# ESP32-P4 register map
Vendor: ESPRESSIF SYSTEMS (SHANGHAI) CO., LTD.; Series: ESP32 P-Series; File version: 2
CPU: RV32IMAFC r0p0, little endian, no MPU, FPU, 0 interrupt priority bits
Address unit: 32 bits
Registers are 32-bit, read-write, reset 0x0 unless marked. A register's access mark holds for its fields unless they carry their own. Offsets are from the block's base; [hi:lo] are bit positions; {n}, {i} and the like mark numbered series.

## LP_WDT — Low-power Watchdog Timer
Base 0x50116000
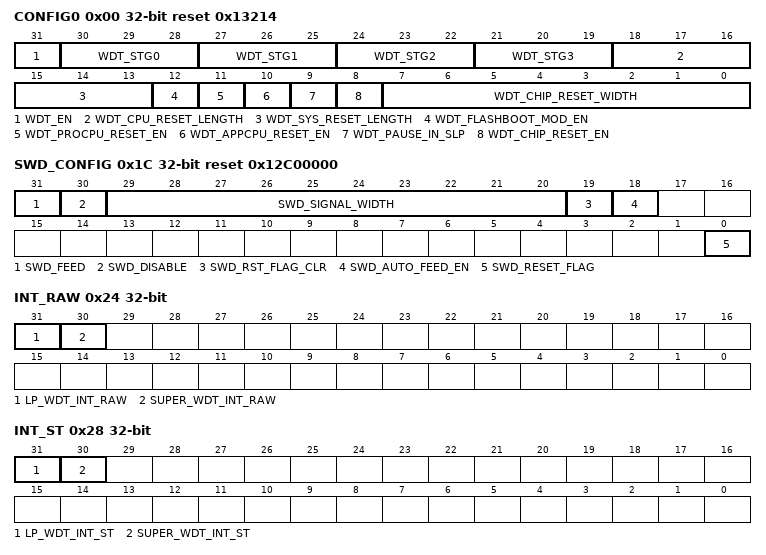
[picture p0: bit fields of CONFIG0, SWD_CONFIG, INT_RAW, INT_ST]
0x00 CONFIG0 reset 0x13214 — need_des
  [31] WDT_EN — need_des
  [30-3n:28-3n] WDT_STG{n} (n=0..3) — need_des
  [18:16] WDT_CPU_RESET_LENGTH — need_des
  [15:13] WDT_SYS_RESET_LENGTH — need_des
  [12] WDT_FLASHBOOT_MOD_EN — need_des
  [11] WDT_PROCPU_RESET_EN — need_des
  [10] WDT_APPCPU_RESET_EN — need_des
  [9] WDT_PAUSE_IN_SLP — need_des
  [8] WDT_CHIP_RESET_EN — need_des
  [7:0] WDT_CHIP_RESET_WIDTH — need_des
0x04 CONFIG1 reset 0x30D40 — need_des
  [31:0] WDT_STG0_HOLD
0x08 CONFIG2 reset 0x13880 — need_des
  [31:0] WDT_STG1_HOLD
0x0C CONFIG3 reset 0xFFF — need_des
  [31:0] WDT_STG2_HOLD
0x10 CONFIG4 reset 0xFFF — need_des
  [31:0] WDT_STG3_HOLD
0x14 FEED wo — need_des
  [31] FEED
0x18 WPROTECT — need_des
  [31:0] WDT_WKEY
0x1C SWD_CONFIG access per field reset 0x12C00000 — need_des
  [31] SWD_FEED wo — need_des
  [30] SWD_DISABLE rw — need_des
  [29:20] SWD_SIGNAL_WIDTH rw — need_des
  [19] SWD_RST_FLAG_CLR wo — need_des
  [18] SWD_AUTO_FEED_EN rw — need_des
  [0] SWD_RESET_FLAG ro — need_des
0x20 SWD_WPROTECT — need_des
  [31:0] SWD_WKEY
0x24 INT_RAW — need_des
  [31] LP_WDT_INT_RAW — need_des
  [30] SUPER_WDT_INT_RAW — need_des
0x28 INT_ST ro — need_des
  [31] LP_WDT_INT_ST — need_des
  [30] SUPER_WDT_INT_ST — need_des
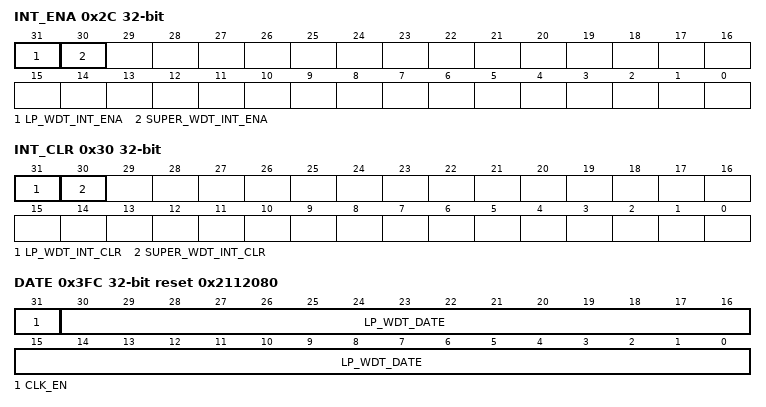
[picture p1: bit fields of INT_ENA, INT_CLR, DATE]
0x2C INT_ENA — need_des
  [31] LP_WDT_INT_ENA — need_des
  [30] SUPER_WDT_INT_ENA — need_des
0x30 INT_CLR wo — need_des
  [31] LP_WDT_INT_CLR — need_des
  [30] SUPER_WDT_INT_CLR — need_des
0x3FC DATE reset 0x2112080 — need_des
  [31] CLK_EN — need_des
  [30:0] LP_WDT_DATE — need_des

## SHA — SHA (Secure Hash Algorithm) Accelerator
Base 0x50091000
0x00 MODE — Initial configuration register.
  [2:0] MODE — Sha mode.
0x04 T_STRING — SHA 512/t configuration register 0.
  [31:0] T_STRING — Sha t_string (used if and only if mode == SHA_512/t).
0x08 T_LENGTH — SHA 512/t configuration register 1.
  [5:0] T_LENGTH — Sha t_length (used if and only if mode == SHA_512/t).
0x0C DMA_BLOCK_NUM — DMA configuration register 0.
  [5:0] DMA_BLOCK_NUM — Dma-sha block number.
0x10 START ro — Typical SHA configuration register 0.
  [31:1] START — Reserved.
0x14 CONTINUE ro — Typical SHA configuration register 1.
  [31:1] CONTINUE — Reserved.
0x18 BUSY ro
  [0] STATE — Sha busy state. 1'b0: idle. 1'b1: busy.
0x1C DMA_START wo — DMA configuration register 1.
  [0] DMA_START — Start dma-sha.
0x20 DMA_CONTINUE wo — DMA configuration register 2.
  [0] DMA_CONTINUE — Continue dma-sha.
0x24 CLEAR_IRQ wo — Interrupt clear register.
  [0] CLEAR_INTERRUPT — Clear sha interrupt.
0x28 IRQ_ENA — Interrupt enable register.
  [0] INTERRUPT_ENA — Sha interrupt enable register. 1'b0: disable(default). 1'b1: enable.
0x2C DATE reset 0x20201229
  [29:0] DATE — Sha date information/ sha version information.
{0x40+4i} H_MEM[{i}] (i=0..15) access not given — Sha H memory which contains intermediate hash or finial hash.
{0x80+4i} M_MEM[{i}] (i=0..15) access not given — Sha M memory which contains message.

## LP_TSENS — Low-power Temperature Sensor
Base 0x5012F000
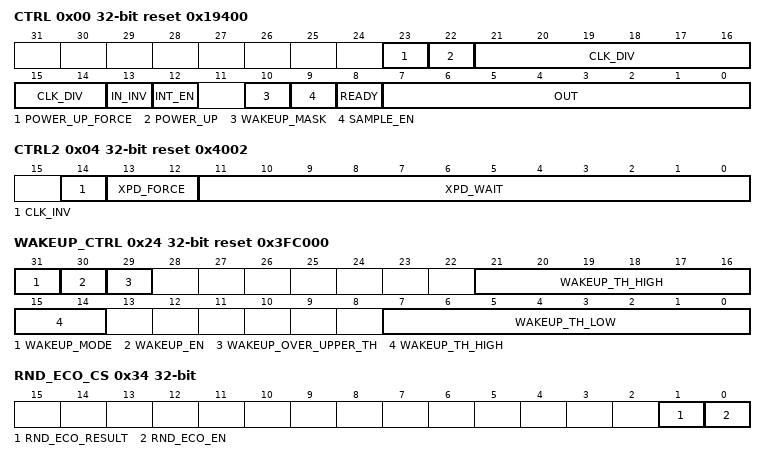
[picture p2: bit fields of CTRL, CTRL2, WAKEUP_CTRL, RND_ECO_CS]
0x00 CTRL access per field reset 0x19400 — Tsens configuration.
  [23] POWER_UP_FORCE rw — 1: dump out & power up controlled by SW, 0: by FSM.
  [22] POWER_UP rw — Temperature sensor power up.
  [21:14] CLK_DIV rw — Temperature sensor clock divider.
  [13] IN_INV rw — Invert temperature sensor data.
  [12] INT_EN rw — Enable temperature sensor to send out interrupt.
  [10] WAKEUP_MASK rw — Wake up signal mask.
  [9] SAMPLE_EN rw — Enable sample signal for wakeup module.
  [8] READY ro — Indicate temperature sensor out ready.
  [7:0] OUT ro — Temperature sensor data out.
0x04 CTRL2 reset 0x4002 — Tsens configuration.
  [14] CLK_INV, [13:12] XPD_FORCE, [11:0] XPD_WAIT
0x08 INT_RAW — Tsens interrupt raw registers.
  [0] COCPU_TSENS_WAKE_INT_RAW — Tsens wakeup interrupt raw.
0x0C INT_ST ro — Tsens interrupt status registers.
  [0] COCPU_TSENS_WAKE_INT_ST — Tsens wakeup interrupt status.
0x10 INT_ENA — Tsens interrupt enable registers.
  [0] COCPU_TSENS_WAKE_INT_ENA — Tsens wakeup interrupt enable.
0x14 INT_CLR wo — Tsens interrupt clear registers.
  [0] COCPU_TSENS_WAKE_INT_CLR — Tsens wakeup interrupt clear.
0x18 CLK_CONF — Tsens regbank configuration registers.
  [0] CLK_EN — Tsens regbank clock gating enable.
0x1C INT_ENA_W1TS wo — Tsens wakeup interrupt enable assert.
  [0] COCPU_TSENS_WAKE_INT_ENA_W1TS — Write 1 to this field to assert interrupt enable.
0x20 INT_ENA_W1TC wo — Tsens wakeup interrupt enable deassert.
  [0] COCPU_TSENS_WAKE_INT_ENA_W1TC — Write 1 to this field to deassert interrupt enable.
0x24 WAKEUP_CTRL access per field reset 0x3FC000 — Tsens wakeup control registers.
  [31] WAKEUP_MODE rw — 0:absolute value comparison mode. 1: relative value comparison mode.
  [30] WAKEUP_EN rw — Tsens wakeup enable.
  [29] WAKEUP_OVER_UPPER_TH ro — Indicates that this wakeup event arose from exceeding upper threshold.
  [21:14] WAKEUP_TH_HIGH rw — Upper threshold.
  [7:0] WAKEUP_TH_LOW rw — Lower threshold.
0x28 SAMPLE_RATE reset 0x14 — Hardware automatic sampling control registers.
  [15:0] SAMPLE_RATE — Hardware automatic sampling rate.
0x2C RND_ECO_LOW
0x30 RND_ECO_HIGH reset 0xFFFFFFFF
0x34 RND_ECO_CS access per field
  [1] RND_ECO_RESULT ro, [0] RND_ECO_EN rw

## USB_WRAP — USB_WRAP Peripheral
Base 0x50080000
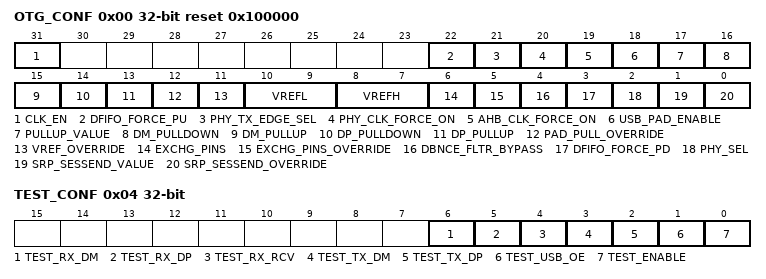
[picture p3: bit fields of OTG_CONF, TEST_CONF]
0x00 OTG_CONF reset 0x100000 — USB wrapper configuration registers.
  [31] CLK_EN — Disable auto clock gating of CSR registers.
  [22] DFIFO_FORCE_PU — Disable the dfifo to go into low power mode. The data in dfifo will not lost.
  [21] PHY_TX_EDGE_SEL — Select phy tx signal output clock edge. 1'b0: negedge, 1'b1: posedge.
  [20] PHY_CLK_FORCE_ON — Force phy clock always on.
  [19] AHB_CLK_FORCE_ON — Force ahb clock always on.
  [18] USB_PAD_ENABLE — Enable USB pad function.
  [17] PULLUP_VALUE — Controlle pullup value. 1'b0: typical value is 2.4K, 1'b1: typical value is 1.2K.
  [16] DM_PULLDOWN — Controlle USB D+ pulldown.
  [15] DM_PULLUP — Controlle USB D+ pullup.
  [14] DP_PULLDOWN — Controlle USB D+ pulldown.
  [13] DP_PULLUP — Controlle USB D+ pullup.
  [12] PAD_PULL_OVERRIDE — Enable software controlle USB D+ D- pullup pulldown.
  [11] VREF_OVERRIDE — Enable software controlle input threshold.
  [10:9] VREFL — Control single-end input low threshold,0.8V to 1.04V, step 80mV.
  [8:7] VREFH — Control single-end input high threshold,1.76V to 2V, step 80mV.
  [6] EXCHG_PINS — USB D+ D- exchange. 1'b0: don't change, 1'b1: exchange D+ D-.
  [5] EXCHG_PINS_OVERRIDE — Enable software controlle USB D+ D- exchange
  [4] DBNCE_FLTR_BYPASS — Bypass Debounce filters for avalid,bvalid,vbusvalid,session end, id signals
  [3] DFIFO_FORCE_PD — Force the dfifo to go into low power mode. The data in dfifo will not lost.
  [2] PHY_SEL — Select internal external PHY. 1'b0: Select internal PHY, 1'b1: Select external PHY.
  [1] SRP_SESSEND_VALUE — Software over-ride value of srp session end signal.
  [0] SRP_SESSEND_OVERRIDE — This bit is used to enable the software over-ride of srp session end signal. 1'b0: the signal is controlled by the chip input, 1'b1: the signal is controlled by the software.
0x04 TEST_CONF access per field — USB wrapper test configuration registers.
  [6] TEST_RX_DM ro — USB D- rx value in test.
  [5] TEST_RX_DP ro — USB D+ rx value in test.
  [4] TEST_RX_RCV ro — USB differential rx value in test.
  [3] TEST_TX_DM rw — USB D- tx value in test.
  [2] TEST_TX_DP rw — USB D+ tx value in test.
  [1] TEST_USB_OE rw — USB pad oen in test.
  [0] TEST_ENABLE rw — Enable test of the USB pad.
0x3FC DATE ro reset 0x23030504
  [31:0] USB_WRAP_DATE
